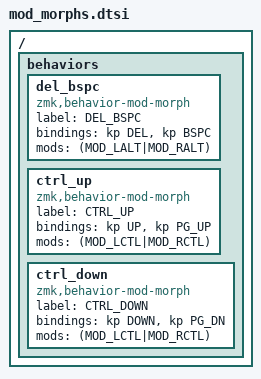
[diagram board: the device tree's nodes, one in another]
/ {
	behaviors {
		del_bspc: del_bspc {
			compatible = "zmk,behavior-mod-morph";
			label = "DEL_BSPC";
			bindings = <&kp DEL>, <&kp BSPC>;
			#binding-cells = <0>;
			mods = <(MOD_LALT|MOD_RALT)>;
		};

		ctrl_up: ctrl_up {
			compatible = "zmk,behavior-mod-morph";
			label = "CTRL_UP";
			bindings = <&kp UP>, <&kp PG_UP>;
			#binding-cells = <0>;
			mods = <(MOD_LCTL|MOD_RCTL)>;
		};
        ctrl_down: ctrl_down {
			compatible = "zmk,behavior-mod-morph";
			label = "CTRL_DOWN";
			bindings = <&kp DOWN>, <&kp PG_DN>;
			#binding-cells = <0>;
			mods = <(MOD_LCTL|MOD_RCTL)>;
		};
	};
};
